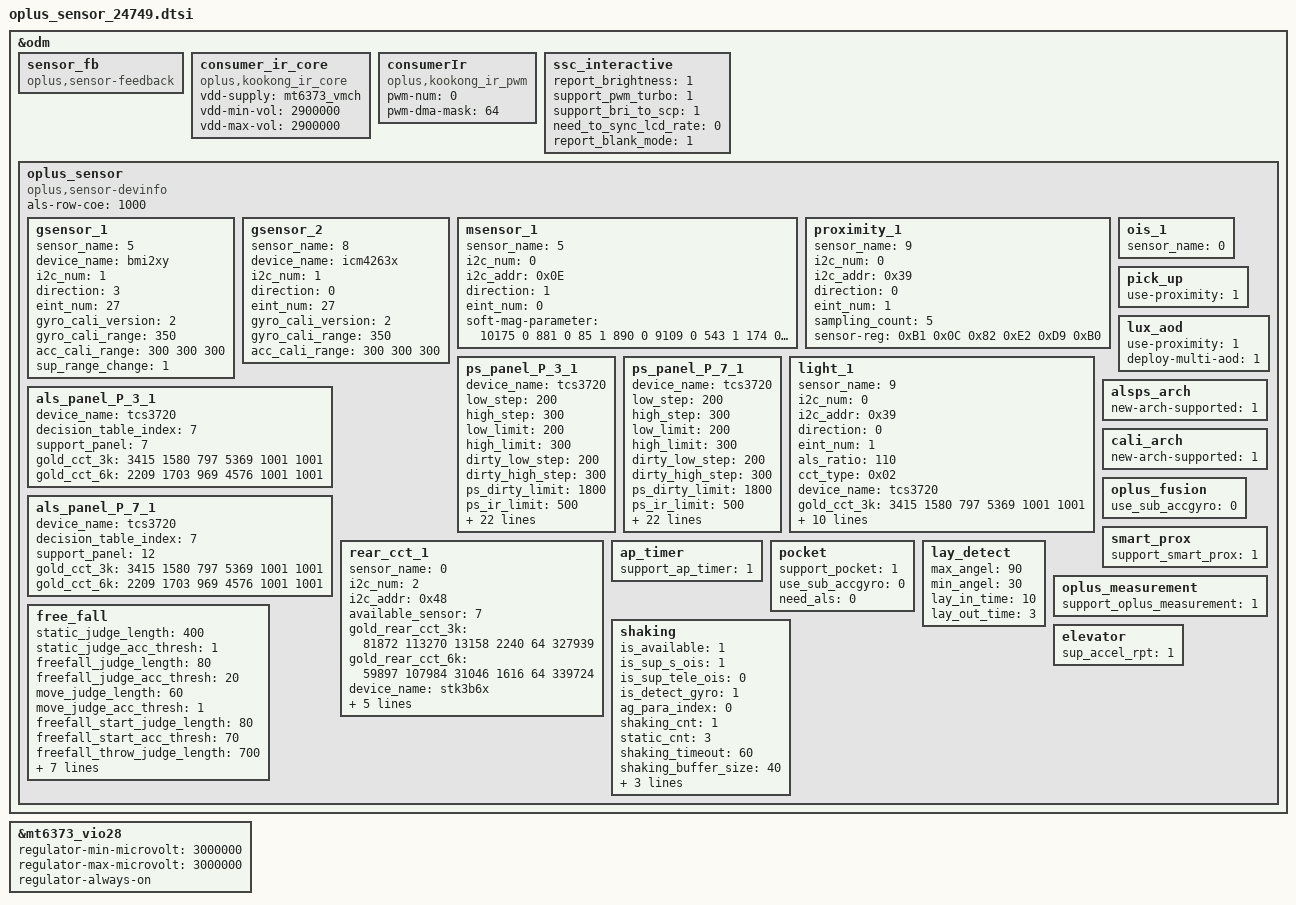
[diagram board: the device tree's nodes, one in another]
&odm {
	sensor_fb: sensor_fb {
		compatible = "oplus,sensor-feedback";
	};
	consumer_ir_core: consumer_ir_core {
		compatible = "oplus,kookong_ir_core";
		status = "okay";
		vdd-supply = <&mt6373_vmch>;
		vdd-min-vol = <2900000>;
		vdd-max-vol = <2900000>;
	};
	consumerIr: consumerIr {
		compatible = "oplus,kookong_ir_pwm";
		status = "okay";
		pwm-num = <0>;
		pwm-dma-mask = <64>;
	};
	ssc_interactive: ssc_interactive {
		report_brightness = <1>;
		support_pwm_turbo = <1>;
		support_bri_to_scp = <1>;
		need_to_sync_lcd_rate = <0>;
		report_blank_mode = <1>;
	};
	oplus_sensor:oplus_sensor {
		compatible = "oplus,sensor-devinfo";
		als-row-coe = <1000>;
		/* sensor start */
		/*
		enum {
			LIS3DH,
			LSM6DS3,
			BMI160,
			LIS2HH12,
			LSM6DSM,
			BMI2XY,
			LSM6DSO,
			ICM4X6XX,
			ICM4263X,
			ICM4N607,
			BMI22X,
			SC7A20,
			MC34X9,
		};
		*/
		gsensor_1: gsensor_1 {
			status = "okay";
			sensor_name = <5>;//BMI2XY
			device_name = "bmi2xy";
			i2c_num = <1>;
			direction = <3>;
			eint_num = <27>;
			gyro_cali_version= <2>;
			gyro_cali_range =<350>;
			acc_cali_range= <300 300 300>;
			sup_range_change = <1>;
		};
		gsensor_2: gsensor_2 {
			status = "okay";
			sensor_name = <8>;//icm4263x
			device_name = "icm4263x";
			i2c_num = <1>;
			direction = <0>;
			eint_num = <27>;
			gyro_cali_version= <2>;
			gyro_cali_range =<350>;
			acc_cali_range= <300 300 300>;
		};

		/*
		enum {
			AKM09911,
			MMC3530,
			MMC5603,
			MXG4300,
			AKM09918,
			AKM09919,
		};
		*/
		msensor_1: msensor_1 {
			status = "okay";
			sensor_name = <5>;//AKM09919
			i2c_num = <0>;
			i2c_addr = <0x0E>;
			direction = <1>;
			eint_num = <0>;
			soft-mag-parameter = <10175 0 881 0 85 1 890 0 9109 0 543 1 174 0 1401 1 11058 0>;
		};
		/*
		enum {
			TMD2725,
			APSD9922,
			STK3335,
			STK3331,
			STK2232,
			TCS3701,
			STK32600,
			STK33502,
			MN78911,
			TCS3720,
		};
		*/
		proximity_1: proximity_1 {
			status = "okay";
			sensor_name = <9>;//TCS3720
			i2c_num = <0>;
			i2c_addr = <0x39>;
			direction = <0>;
			eint_num = <1>;
			sampling_count = <5>;
			sensor-reg = <0xB1 0x0C 0x82 0xE2 0xD9 0xB0>;
		};
		ps_panel_P_3_1: ps_panel_P_3_1 {
			status = "okay";
			device_name = "tcs3720";
			low_step = <200>;
			high_step = <300>;
			low_limit = <200>;
			high_limit = <300>;
			dirty_low_step = <200>;
			dirty_high_step = <300>;
			ps_dirty_limit = <1800>;
			ps_ir_limit = <500>;
			ps_adjust_min = <0>;
			ps_adjust_max = <850>;
			step_max = <300>;
			step_min = <200>;
			step_div = <2000>;
			anti_shake_delta = <100>;
			dynamic_cali_max = <5000>;
			raw2offset_radio = <1000>;
			offset_max = <16000>;
			offset_range_min = <0>;
			offset_range_max = <65534>;
			force_cali_limit = <0>;
			cali_jitter_limit = <80>;
			cal_offset_margin = <3001>;
			60hz_psd_us = <2650>;
			90hz_psd_us = <2650>;
			120hz_psd_us = <2650>;
			ps_check_num = <3>;
			ps_mid_filter = <1>;
			need_to_sync_lcd_rate = <0>;
			dmc_flt_thr = <100>;
			ps_power_config = <7>;
		};
		ps_panel_P_7_1: ps_panel_P_7_1 {
			status = "okay";
			device_name = "tcs3720";
			low_step = <200>;
			high_step = <300>;
			low_limit = <200>;
			high_limit = <300>;
			dirty_low_step = <200>;
			dirty_high_step = <300>;
			ps_dirty_limit = <1800>;
			ps_ir_limit = <500>;
			ps_adjust_min = <0>;
			ps_adjust_max = <850>;
			step_max = <300>;
			step_min = <200>;
			step_div = <2000>;
			anti_shake_delta = <100>;
			dynamic_cali_max = <5000>;
			raw2offset_radio = <1000>;
			offset_max = <16000>;
			offset_range_min = <0>;
			offset_range_max = <65534>;
			force_cali_limit = <0>;
			cali_jitter_limit = <80>;
			cal_offset_margin = <3001>;
			60hz_psd_us = <4000>;
			90hz_psd_us = <4000>;
			120hz_psd_us = <4000>;
			ps_check_num = <3>;
			ps_mid_filter = <1>;
			need_to_sync_lcd_rate = <0>;
			dmc_flt_thr = <100>;
			ps_power_config = <8>;
		};
		light_1: light_1 {
			status = "okay";
			sensor_name = <9>;//TCS3720
			i2c_num = <0>;
			i2c_addr = <0x39>;
			direction = <0>;
			eint_num = <1>;
			als_ratio = <110>;
			cct_type = <0x02>; //0x01 CCT_NORMAL 0x02 CCT_WISE
			device_name = "tcs3720";
			gold_cct_3k = <3415 1580 797 5369 1001 1001>;
			gold_cct_6k = <2209 1703 969 4576 1001 1001>;
			lb_bri_max = <4096>;
			ir_ratio = <10>; // *1000
			als_delay = <390>;
			available_sensor = <14>;
			gold_cct_factor = <941 946 924 966 1001 1001>;
			high_pwm_cct = <1>;
			als_timer_ms = <100>;
			als_buffer_length = <2>;
			need_gain_cali = <1>;
		};
		als_panel_P_3_1: als_panel_P_3_1 {
			status = "okay";
			device_name = "tcs3720";
			decision_table_index = <7>;
			support_panel = <7>; // 1-SAMSUNG, 2-BOE, 3-TIANMA, 4-NT36672C, 5-HX83112F, 6-TM, 7-P_3, 8-P_B
			gold_cct_3k = <3415 1580 797 5369 1001 1001>;
			gold_cct_6k = <2209 1703 969 4576 1001 1001>;
		};
		als_panel_P_7_1: als_panel_P_7_1 {
			status = "okay";
			device_name = "tcs3720";
			decision_table_index = <7>;
			support_panel = <12>; // 1-SAMSUNG, 2-BOE, 3-TIANMA, 4-NT36672C, 5-HX83112F, 6-TM, 7-P_3, 8-P_B
			gold_cct_3k = <3415 1580 797 5369 1001 1001>;
			gold_cct_6k = <2209 1703 969 4576 1001 1001>;
		};
		/*
		enum {
			STK37600,
			MN29005,
			TCS3408,
			TCS3449,
		};
		*/
		rear_cct_1: rear_cct_1 {
			status = "okay";
			sensor_name = <0>; // stk37600
			i2c_num = <2>;
			i2c_addr = <0x48>;
			available_sensor = <7>; // bit 0: rear als, bit 1: rear cct, bit 2: rear flicker, bit 3: rear proximity
			gold_rear_cct_3k = <81872 113270 13158 2240 64 327939>; // 3000k gold parameter R, G, B, C, W, F
			gold_rear_cct_6k = <59897 107984 31046 1616 64 339724>; // 6000k gold parameter R, G, B, C, W, F
			device_name = "stk3b6x";
			cct_coef_Hir = <15874160 0 3985120 1 9590780 0 1659320 1
							14825800 0 3769800 1 12804810 0 2078960 1
							4098240 0 2661910 1 31866590 0 1713910 1>;
			cct_coef_Lir = <8527610 0 1342380 0 10884040 0 5013910 0
							1399380 0 5725030 0 8660750 0 19840310 0
							2420590 0 2011130 1 39859710 0 37647410 1>;
			gold_rear_cct_factor = <947 990 906 836 1001 941>;
		};

		ois_1: ois_1 {
			status = "okay";
			sensor_name = <0>;
		};
		pick_up: pick_up {
			status = "okay";
			use-proximity = <1>;
		};
		lux_aod: lux_aod {
			status = "okay";
			use-proximity = <1>;
			deploy-multi-aod = <1>;
		};
		alsps_arch: alsps_arch {
			status = "okay";
			new-arch-supported = <1>;
		};
		cali_arch: cali_arch {
			status = "okay";
			new-arch-supported = <1>;
		};
		oplus_fusion: oplus_fusion {
			status = "okay";
			use_sub_accgyro = <0>;
		};
		smart_prox: smart_prox {
			status = "okay";
			support_smart_prox = <1>;
		};
		ap_timer: ap_timer {
			status = "okay";
			support_ap_timer = <1>;
		};
		pocket: pocket {
			status = "okay";
			support_pocket = <1>;
			use_sub_accgyro = <0>;
			need_als = <0>;
		};
		lay_detect: lay_detect{
			status = "okay";
			max_angel = <90>;
			min_angel = <30>;
			lay_in_time = <10>;
			lay_out_time = <3>;
		};
		free_fall: free_fall{
			status = "okay";
			static_judge_length = <400>;
			static_judge_acc_thresh = <1>;
			freefall_judge_length = <80>;
			freefall_judge_acc_thresh = <20>;
			move_judge_length = <60>;
			move_judge_acc_thresh = <1>;
			freefall_start_judge_length  = <80>;
			freefall_start_acc_thresh = <70>;
			freefall_throw_judge_length = <700>;
			freefall_throw_acc_thresh = <50>;
			freefall_end_acc_thresh = <30>;
			freefall_valid_time_length = <1000>;
			freefall_peek_time_length = <800>;
			freefall_peek_acc_thresh = <60>;
			freefall_material_thresh = <900>;
			valid_peek_interval_thresh = <10000>;
		};
		oplus_measurement: oplus_measurement{
			status = "okay";
			support_oplus_measurement = <1>;
		};
		shaking: shaking{
			status = "okay";
			is_available = <1>;
			is_sup_s_ois = <1>;
			is_sup_tele_ois = <0>;
			is_detect_gyro = <1>;

			ag_para_index = <0>;
			shaking_cnt = <1>;
			static_cnt = <3>;
			shaking_timeout = <60>;
			shaking_buffer_size = <40>;
			acc_static_length = <100>;
			acc_move_threshold = <600>;
			acc_move_length = <10>;
		};
		elevator: elevator{
			status = "okay";
			sup_accel_rpt = <1>;
		};
	};
/* sensor end */
};

&mt6373_vio28 {
	regulator-min-microvolt = <3000000>;
	regulator-max-microvolt = <3000000>;
	regulator-always-on;
};
